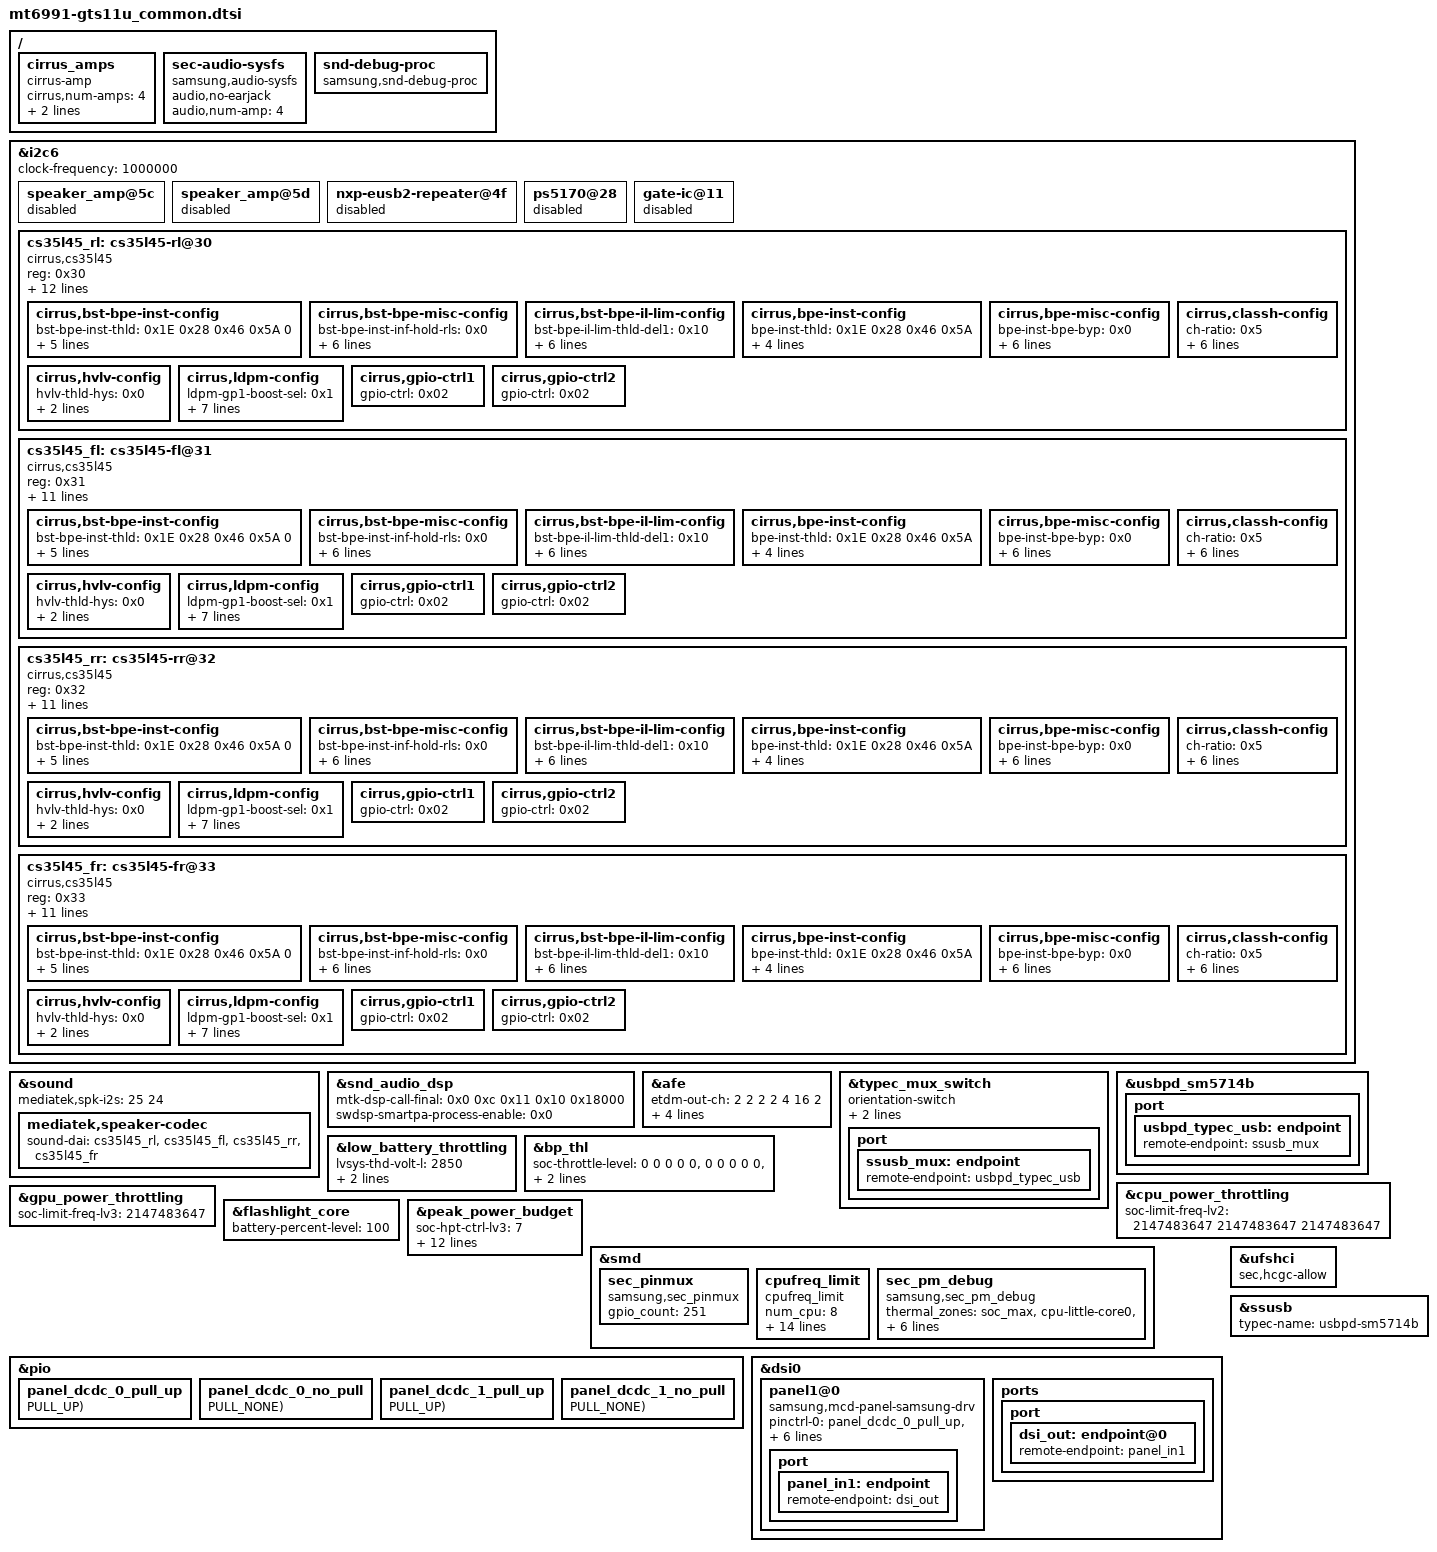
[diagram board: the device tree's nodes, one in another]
/* Generated by Samsung for MTK vendor board
 * If these files should be changed, then please make a sync with MTK
*/

/* Add Samsung configuration over here */

/ {
	fragment@model {
		target-path = "/";
		__overlay__ {
			cirrus_amps {
				compatible = "cirrus-amp";
				cirrus,num-amps = <4>;
				/* i2c addr 0x30, 0x31, 0x32, 0x33 */
				cirrus,amps = <&cs35l45_rl &cs35l45_fl &cs35l45_rr &cs35l45_fr>;
			};

			sec-audio-sysfs {
				compatible = "samsung,audio-sysfs";
				status = "okay";
				audio,no-earjack;
				audio,num-amp = <4>;
			};

			snd-debug-proc {
				compatible = "samsung,snd-debug-proc";
				status = "okay";
			};

		}; /* end of __overlay__ */
	}; /* end of fragment */
}; /* end of root */

&i2c6 {
	speaker_amp@5c {
		status = "disabled";
	};

	speaker_amp@5d {
		status = "disabled";
	};

	nxp-eusb2-repeater@4f {
		status = "disabled";
	};

	ps5170@28 {
		status = "disabled";
	};

	gate-ic@11 {
		status = "disabled";
	};
};

&i2c6 {
	clock-frequency = <1000000>;

	cs35l45_rl: cs35l45-rl@30 {
		compatible = "cirrus,cs35l45";
		#sound-dai-cells = <0>;
		reg = <0x30>;
		status = "okay";
		interrupt-parent = <&pio>;
		interrupts = <5 8>;
		reset-gpios = <&pio 91 0>;
		sound-name-prefix = "RL"; /* RearLeft */
		cirrus,mfd-suffix = "";
		cirrus,bd-suffix = "_2";
		cirrus,use-tdm-slots;
		cirrus,asp-sdout-hiz-ctrl = <0x3>;

		cirrus,ngate-ch1-hold = <0x2>;
		cirrus,ngate-ch1-thr = <0x6>;
		cirrus,ngate-ch2-hold = <0x2>;
		cirrus,ngate-ch2-thr = <0x6>;

		cirrus,bst-bpe-inst-config {
			bst-bpe-inst-thld = <0x1E 0x28 0x46 0x5A 0>;
			bst-bpe-inst-ilim = <0 0x04 0x0C 0x14 0x3C>;
			bst-bpe-inst-ss-ilim = <0 0x00 0x04 0x08 0x1C>;
			bst-bpe-inst-atk-rate = <0 0x3 0x6 0x6 0>;
			bst-bpe-inst-hold-time = <0x2 0x2 0x2 0x2 0>;
			bst-bpe-inst-rls-rate = <0x06 0x06 0x06 0x06 0>;
		};

		cirrus,bst-bpe-misc-config {
			bst-bpe-inst-inf-hold-rls = <0x0>;
			bst-bpe-il-lim-mode = <0x0>;
			bst-bpe-out-opmode-sel = <0x0>;
			bst-bpe-inst-l3-byp = <0x1>;
			bst-bpe-inst-l2-byp = <0x1>;
			bst-bpe-inst-l1-byp = <0x0>;
			bst-bpe-filt-sel = <0x0>;
		};

		cirrus,bst-bpe-il-lim-config {
			bst-bpe-il-lim-thld-del1 = <0x10>;
			bst-bpe-il-lim-thld-del2 = <0x00>;
			bst-bpe-il-lim1-thld = <0x2c>;
			bst-bpe-il-lim-thld-hyst = <0x00>;
			bst-bpe-il-lim-dly-hyst = <0x00>;
			bst-bpe-il-lim2-dly = <0x04>;
			bst-bpe-il-lim1-dly = <0x04>;
		};

		cirrus,bpe-inst-config {
			bpe-inst-thld = <0x1E 0x28 0x46 0x5A>;
			bpe-inst-attn = <0x0A 0x06 0x0C 0x06>;
			bpe-inst-atk-rate = <0x00 0x01 0x06 0x06>;
			bpe-inst-hold-time = <0x02 0x02 0x02 0x02>;
			bpe-inst-rls-rate = <0x0A 0x08 0x05 0x05>;
		};

		cirrus,bpe-misc-config {
			bpe-inst-bpe-byp = <0x0>;
			bpe-inst-inf-hold-rls = <0x0>;
			bpe-inst-l3-byp = <0x1>;
			bpe-inst-l2-byp = <0x1>;
			bpe-inst-l1-byp = <0x0>;
			bpe-mode-sel = <0x0>;
			bpe-filt-sel = <0x0>;
		};

		cirrus,classh-config {
			ch-ratio = <0x5>;
			ch-rel-rate = <0x4>;
			ch-ovb-thld1 = <0x82>;
			ch-ovb-thlddelta = <0x28>;
			ch-vdd-bst-max = <0xFA>;
			ch-ovb-ratio = <0x01>;
			ch-thld1-offset = <0x02d>;
		};

		cirrus,hvlv-config {
			hvlv-thld-hys = <0x0>;
			hvlv-thld = <0x8>;
			hvlv-dly = <0x1>;
		};

		cirrus,ldpm-config {
			ldpm-gp1-boost-sel = <0x1>;
			ldpm-gp1-amp-sel = <0x1>;
			ldpm-gp1-delay = <0x6>;
			ldpm-gp1-pcm-thld = <0x6>;
			ldpm-gp2-imon-sel = <0x1>;
			ldpm-gp2-vmon-sel = <0x1>;
			ldpm-gp2-delay = <0x6>;
			ldpm-gp2-pcm-thld = <0x6>;
		};

		cirrus,gpio-ctrl1 {
			gpio-ctrl = <0x02>;
		};
		cirrus,gpio-ctrl2 {
			gpio-ctrl = <0x02>;
		};
	};

	cs35l45_fl: cs35l45-fl@31 {
		compatible = "cirrus,cs35l45";
		#sound-dai-cells = <0>;
		reg = <0x31>;
		status = "okay";
		interrupt-parent = <&pio>;
		interrupts = <5 8>;
		/* reset-gpios = <&pio 91 0>; */
		sound-name-prefix = "FL"; /* FrontLeft */
		cirrus,mfd-suffix = "_b";
		cirrus,bd-suffix = "_0";
		cirrus,use-tdm-slots;
		cirrus,asp-sdout-hiz-ctrl = <0x3>;

		cirrus,ngate-ch1-hold = <0x2>;
		cirrus,ngate-ch1-thr = <0x6>;
		cirrus,ngate-ch2-hold = <0x2>;
		cirrus,ngate-ch2-thr = <0x6>;

		cirrus,bst-bpe-inst-config {
			bst-bpe-inst-thld = <0x1E 0x28 0x46 0x5A 0>;
			bst-bpe-inst-ilim = <0 0x04 0x0C 0x14 0x3C>;
			bst-bpe-inst-ss-ilim = <0 0x00 0x04 0x08 0x1C>;
			bst-bpe-inst-atk-rate = <0 0x3 0x6 0x6 0>;
			bst-bpe-inst-hold-time = <0x2 0x2 0x2 0x2 0>;
			bst-bpe-inst-rls-rate = <0x06 0x06 0x06 0x06 0>;
		};

		cirrus,bst-bpe-misc-config {
			bst-bpe-inst-inf-hold-rls = <0x0>;
			bst-bpe-il-lim-mode = <0x0>;
			bst-bpe-out-opmode-sel = <0x0>;
			bst-bpe-inst-l3-byp = <0x1>;
			bst-bpe-inst-l2-byp = <0x1>;
			bst-bpe-inst-l1-byp = <0x0>;
			bst-bpe-filt-sel = <0x0>;
		};

		cirrus,bst-bpe-il-lim-config {
			bst-bpe-il-lim-thld-del1 = <0x10>;
			bst-bpe-il-lim-thld-del2 = <0x00>;
			bst-bpe-il-lim1-thld = <0x2c>;
			bst-bpe-il-lim-thld-hyst = <0x00>;
			bst-bpe-il-lim-dly-hyst = <0x00>;
			bst-bpe-il-lim2-dly = <0x04>;
			bst-bpe-il-lim1-dly = <0x04>;
		};

		cirrus,bpe-inst-config {
			bpe-inst-thld = <0x1E 0x28 0x46 0x5A>;
			bpe-inst-attn = <0x0A 0x06 0x0C 0x06>;
			bpe-inst-atk-rate = <0x00 0x01 0x06 0x06>;
			bpe-inst-hold-time = <0x02 0x02 0x02 0x02>;
			bpe-inst-rls-rate = <0x0A 0x08 0x05 0x05>;
		};

		cirrus,bpe-misc-config {
			bpe-inst-bpe-byp = <0x0>;
			bpe-inst-inf-hold-rls = <0x0>;
			bpe-inst-l3-byp = <0x1>;
			bpe-inst-l2-byp = <0x1>;
			bpe-inst-l1-byp = <0x0>;
			bpe-mode-sel = <0x0>;
			bpe-filt-sel = <0x0>;
		};

		cirrus,classh-config {
			ch-ratio = <0x5>;
			ch-rel-rate = <0x4>;
			ch-ovb-thld1 = <0x82>;
			ch-ovb-thlddelta = <0x28>;
			ch-vdd-bst-max = <0xFA>;
			ch-ovb-ratio = <0x01>;
			ch-thld1-offset = <0x02d>;
		};

		cirrus,hvlv-config {
			hvlv-thld-hys = <0x0>;
			hvlv-thld = <0x8>;
			hvlv-dly = <0x1>;
		};

		cirrus,ldpm-config {
			ldpm-gp1-boost-sel = <0x1>;
			ldpm-gp1-amp-sel = <0x1>;
			ldpm-gp1-delay = <0x6>;
			ldpm-gp1-pcm-thld = <0x6>;
			ldpm-gp2-imon-sel = <0x1>;
			ldpm-gp2-vmon-sel = <0x1>;
			ldpm-gp2-delay = <0x6>;
			ldpm-gp2-pcm-thld = <0x6>;
		};

		cirrus,gpio-ctrl1 {
			gpio-ctrl = <0x02>;
		};
		cirrus,gpio-ctrl2 {
			gpio-ctrl = <0x02>;
		};
	};

	cs35l45_rr: cs35l45-rr@32 {
		compatible = "cirrus,cs35l45";
		#sound-dai-cells = <0>;
		reg = <0x32>;
		status = "okay";
		interrupt-parent = <&pio>;
		interrupts = <5 8>;
		/* reset-gpios = <&pio 91 0>; */
		sound-name-prefix = "RR"; /* RearRight */
		cirrus,mfd-suffix = "_r";
		cirrus,bd-suffix = "_3";
		cirrus,use-tdm-slots;
		cirrus,asp-sdout-hiz-ctrl = <0x3>;

		cirrus,ngate-ch1-hold = <0x2>;
		cirrus,ngate-ch1-thr = <0x6>;
		cirrus,ngate-ch2-hold = <0x2>;
		cirrus,ngate-ch2-thr = <0x6>;

		cirrus,bst-bpe-inst-config {
			bst-bpe-inst-thld = <0x1E 0x28 0x46 0x5A 0>;
			bst-bpe-inst-ilim = <0 0x04 0x0C 0x14 0x3C>;
			bst-bpe-inst-ss-ilim = <0 0x00 0x04 0x08 0x1C>;
			bst-bpe-inst-atk-rate = <0 0x3 0x6 0x6 0>;
			bst-bpe-inst-hold-time = <0x2 0x2 0x2 0x2 0>;
			bst-bpe-inst-rls-rate = <0x06 0x06 0x06 0x06 0>;
		};

		cirrus,bst-bpe-misc-config {
			bst-bpe-inst-inf-hold-rls = <0x0>;
			bst-bpe-il-lim-mode = <0x0>;
			bst-bpe-out-opmode-sel = <0x0>;
			bst-bpe-inst-l3-byp = <0x1>;
			bst-bpe-inst-l2-byp = <0x1>;
			bst-bpe-inst-l1-byp = <0x0>;
			bst-bpe-filt-sel = <0x0>;
		};

		cirrus,bst-bpe-il-lim-config {
			bst-bpe-il-lim-thld-del1 = <0x10>;
			bst-bpe-il-lim-thld-del2 = <0x00>;
			bst-bpe-il-lim1-thld = <0x2c>;
			bst-bpe-il-lim-thld-hyst = <0x00>;
			bst-bpe-il-lim-dly-hyst = <0x00>;
			bst-bpe-il-lim2-dly = <0x04>;
			bst-bpe-il-lim1-dly = <0x04>;
		};

		cirrus,bpe-inst-config {
			bpe-inst-thld = <0x1E 0x28 0x46 0x5A>;
			bpe-inst-attn = <0x0A 0x06 0x0C 0x06>;
			bpe-inst-atk-rate = <0x00 0x01 0x06 0x06>;
			bpe-inst-hold-time = <0x02 0x02 0x02 0x02>;
			bpe-inst-rls-rate = <0x0A 0x08 0x05 0x05>;
		};

		cirrus,bpe-misc-config {
			bpe-inst-bpe-byp = <0x0>;
			bpe-inst-inf-hold-rls = <0x0>;
			bpe-inst-l3-byp = <0x1>;
			bpe-inst-l2-byp = <0x1>;
			bpe-inst-l1-byp = <0x0>;
			bpe-mode-sel = <0x0>;
			bpe-filt-sel = <0x0>;
		};

		cirrus,classh-config {
			ch-ratio = <0x5>;
			ch-rel-rate = <0x4>;
			ch-ovb-thld1 = <0x82>;
			ch-ovb-thlddelta = <0x28>;
			ch-vdd-bst-max = <0xFA>;
			ch-ovb-ratio = <0x01>;
			ch-thld1-offset = <0x02d>;
		};

		cirrus,hvlv-config {
			hvlv-thld-hys = <0x0>;
			hvlv-thld = <0x8>;
			hvlv-dly = <0x1>;
		};

		cirrus,ldpm-config {
			ldpm-gp1-boost-sel = <0x1>;
			ldpm-gp1-amp-sel = <0x1>;
			ldpm-gp1-delay = <0x6>;
			ldpm-gp1-pcm-thld = <0x6>;
			ldpm-gp2-imon-sel = <0x1>;
			ldpm-gp2-vmon-sel = <0x1>;
			ldpm-gp2-delay = <0x6>;
			ldpm-gp2-pcm-thld = <0x6>;
		};

		cirrus,gpio-ctrl1 {
			gpio-ctrl = <0x02>;
		};
		cirrus,gpio-ctrl2 {
			gpio-ctrl = <0x02>;
		};
	};

	cs35l45_fr: cs35l45-fr@33 {
		compatible = "cirrus,cs35l45";
		#sound-dai-cells = <0>;
		reg = <0x33>;
		status = "okay";
		interrupt-parent = <&pio>;
		interrupts = <5 8>;
		/* reset-gpios = <&pio 91 0>; */
		sound-name-prefix = "FR"; /* FrontRight */
		cirrus,mfd-suffix = "_br";
		cirrus,bd-suffix = "_1";
		cirrus,use-tdm-slots;
		cirrus,asp-sdout-hiz-ctrl = <0x3>;

		cirrus,ngate-ch1-hold = <0x2>;
		cirrus,ngate-ch1-thr = <0x6>;
		cirrus,ngate-ch2-hold = <0x2>;
		cirrus,ngate-ch2-thr = <0x6>;

		cirrus,bst-bpe-inst-config {
			bst-bpe-inst-thld = <0x1E 0x28 0x46 0x5A 0>;
			bst-bpe-inst-ilim = <0 0x04 0x0C 0x14 0x3C>;
			bst-bpe-inst-ss-ilim = <0 0x00 0x04 0x08 0x1C>;
			bst-bpe-inst-atk-rate = <0 0x3 0x6 0x6 0>;
			bst-bpe-inst-hold-time = <0x2 0x2 0x2 0x2 0>;
			bst-bpe-inst-rls-rate = <0x06 0x06 0x06 0x06 0>;
		};

		cirrus,bst-bpe-misc-config {
			bst-bpe-inst-inf-hold-rls = <0x0>;
			bst-bpe-il-lim-mode = <0x0>;
			bst-bpe-out-opmode-sel = <0x0>;
			bst-bpe-inst-l3-byp = <0x1>;
			bst-bpe-inst-l2-byp = <0x1>;
			bst-bpe-inst-l1-byp = <0x0>;
			bst-bpe-filt-sel = <0x0>;
		};

		cirrus,bst-bpe-il-lim-config {
			bst-bpe-il-lim-thld-del1 = <0x10>;
			bst-bpe-il-lim-thld-del2 = <0x00>;
			bst-bpe-il-lim1-thld = <0x2c>;
			bst-bpe-il-lim-thld-hyst = <0x00>;
			bst-bpe-il-lim-dly-hyst = <0x00>;
			bst-bpe-il-lim2-dly = <0x04>;
			bst-bpe-il-lim1-dly = <0x04>;
		};

		cirrus,bpe-inst-config {
			bpe-inst-thld = <0x1E 0x28 0x46 0x5A>;
			bpe-inst-attn = <0x0A 0x06 0x0C 0x06>;
			bpe-inst-atk-rate = <0x00 0x01 0x06 0x06>;
			bpe-inst-hold-time = <0x02 0x02 0x02 0x02>;
			bpe-inst-rls-rate = <0x0A 0x08 0x05 0x05>;
		};

		cirrus,bpe-misc-config {
			bpe-inst-bpe-byp = <0x0>;
			bpe-inst-inf-hold-rls = <0x0>;
			bpe-inst-l3-byp = <0x1>;
			bpe-inst-l2-byp = <0x1>;
			bpe-inst-l1-byp = <0x0>;
			bpe-mode-sel = <0x0>;
			bpe-filt-sel = <0x0>;
		};

		cirrus,classh-config {
			ch-ratio = <0x5>;
			ch-rel-rate = <0x4>;
			ch-ovb-thld1 = <0x82>;
			ch-ovb-thlddelta = <0x28>;
			ch-vdd-bst-max = <0xFA>;
			ch-ovb-ratio = <0x01>;
			ch-thld1-offset = <0x02d>;
		};

		cirrus,hvlv-config {
			hvlv-thld-hys = <0x0>;
			hvlv-thld = <0x8>;
			hvlv-dly = <0x1>;
		};

		cirrus,ldpm-config {
			ldpm-gp1-boost-sel = <0x1>;
			ldpm-gp1-amp-sel = <0x1>;
			ldpm-gp1-delay = <0x6>;
			ldpm-gp1-pcm-thld = <0x6>;
			ldpm-gp2-imon-sel = <0x1>;
			ldpm-gp2-vmon-sel = <0x1>;
			ldpm-gp2-delay = <0x6>;
			ldpm-gp2-pcm-thld = <0x6>;
		};

		cirrus,gpio-ctrl1 {
			gpio-ctrl = <0x02>;
		};
		cirrus,gpio-ctrl2 {
			gpio-ctrl = <0x02>;
		};
	};
};

&sound {
	mediatek,spk-i2s = <25 24>;
	mediatek,speaker-codec {
		/* i2c addr 0x30, 0x31, 0x32, 0x33 */
		sound-dai = <&cs35l45_rl>, <&cs35l45_fl>, <&cs35l45_rr>, <&cs35l45_fr>;
	};
};

/* feature : $enable $dl_mem $ul_mem $ref_mem $size */
&snd_audio_dsp {
	mtk-dsp-call-final = <0x0 0xc 0x11 0x10 0x18000>;
	swdsp-smartpa-process-enable = <0x0>;
};

&afe {
	etdm-out-ch = <2 2 2 2 4 16 2>;
	etdm-in-ch = <2 2 2 2 4 16 16>;
	etdm-out-format = <0 0 0 0 4 4 4>;
	etdm-in-format = <0 0 0 0 4 4 4>;
	mediatek,ap-dmic = <1>;
};

&typec_mux_switch {
	orientation-switch;
	mode-switch;
	accessory;
	port {
		ssusb_mux: endpoint {
			remote-endpoint = <&usbpd_typec_usb>;
		};
	};
};

&usbpd_sm5714b {
	port {
		usbpd_typec_usb: endpoint {
			remote-endpoint = <&ssusb_mux>;
		};
	};
};

&low_battery_throttling {
	lvsys-thd-volt-l = <2850>;
	lvsys-thd-volt-h = <3100>;
	lvsys-cust-thl-lv = <1>;
};

&bp_thl {
	soc-throttle-level = <0 0 0 0 0>, //temperature stage 0
		<0 0 0 0 0>, //temperature stage 1
		<0 0 0 0 0>, //temperature stage 2
		<0 0 0 0 0>; //temperature stage 3
	soc-limit-threshold = <80 60 30 5>;
};

&cpu_power_throttling {
	soc-limit-freq-lv2 = < 2147483647  2147483647 2147483647 >;
};

&gpu_power_throttling {
	soc-limit-freq-lv3 = <2147483647>;
};

&flashlight_core {
	battery-percent-level = <100>;
};

&peak_power_budget {
	soc-hpt-ctrl-lv3 = <7>;

	/* The HW PT at each battery throttle level. */
	cpub-sf-default = <3>;
	cpum-sf-default = <4>;
	gpu-sf-default = <7>;

	soc-sf-cpub-lv1 = <3>;
	soc-sf-cpum-lv1 = <4>;
	soc-sf-gpu-lv1 = <7>;

	soc-sf-cpub-lv2 = <3>;
	soc-sf-cpum-lv2 = <4>;
	soc-sf-gpu-lv2 = <7>;

	soc-sf-cpub-lv3 = <3>;
	soc-sf-cpum-lv3 = <4>;
	soc-sf-gpu-lv3 = <7>;
};

&smd {

	sec_pinmux {
		status = "okay";
		compatible = "samsung,sec_pinmux";

		gpio_count = <251>;
	};

	cpufreq_limit {
		status = "okay";
		compatible = "cpufreq_limit";

		num_cpu = <8>;
		ltl_cpu_start = <0>;
		mid_cpu_start = <4>;
		big_cpu_start = <7>;
		ltl_min_lock_freq = <1200000>;
		big_max_lock_freq = <800000>;
		ltl_divider = <4>;

		ltl_boost_table = <
			3730000 2400000
			3600000 2300000
			3500000 2200000
			3400000 2100000
			2600000 1800000
			2200000 1500000
			1800000 1300000
			600000 1100000
		>;

		ltl_limit_table = <
			3730000	4294967295	/* 3730000 ~ : max freq */
			3600000 2300000
			3500000 2200000
			3400000 2100000
			2600000 1800000
			2200000 1500000
			1800000 1300000
			600000 1100000
		>;

		mid_boost_table = <
			3730000 3300000
			3600000 3200000
			3500000 3100000
			3300000 3000000
			3200000 2900000
			3100000 2800000
			3000000 2700000
			2900000 2600000
			2800000 2500000
			2700000 2400000
			2600000 2300000
			2500000 2200000
			2400000 2100000
			2300000 2000000
			2200000 1900000
			2100000 1800000
			2000000 1700000
			1900000 1600000
			1800000 1500000
			1700000 1400000
			1600000 1300000
			1500000 1200000
			1400000 1100000
			1300000 1000000
			1200000 900000
			600000 800000
		>;

		mid_limit_table = <
			3730000	4294967295	/* 3730000 ~ : max freq */
			3600000 3200000
			3500000 3100000
			3300000 3000000
			3200000 2900000
			3100000 2800000
			3000000 2700000
			2900000 2600000
			2800000 2500000
			2700000 2400000
			2600000 2300000
			2500000 2200000
			2400000 2100000
			2300000 2000000
			2200000 1900000
			2100000 1800000
			2000000 1700000
			1900000 1600000
			1800000 1500000
			1700000 1400000
			1600000 1300000
			1500000 1200000
			1400000 1100000
			1300000 1000000
			1200000 900000
			600000 800000
		>;

	};

	sec_pm_debug {
	status = "okay";
	compatible = "samsung,sec_pm_debug";

	thermal_zones = "soc_max",
		"cpu-little-core0", "cpu-little-core1", "cpu-little-core2", "cpu-little-core3",
		"cpu-medium-core4-0", "cpu-medium-core4-1", "cpu-medium-core5-0", "cpu-medium-core5-1",
		"cpu-medium-core6-0", "cpu-medium-core6-1", "cpu-big-core7-0", "cpu-big-core7-1",
		"gpu0", "gpu1", "gpu2";
	};
};

&pio {
	panel_dcdc_0_pull_up: panel_dcdc_0_pull_up {
		GPIO_CONFIG_PUD(AP,pio,18, FUNC_INPUT, PULL_UP);
	};

	panel_dcdc_0_no_pull: panel_dcdc_0_no_pull {
		GPIO_CONFIG_PUD(AP,pio,18, FUNC_INPUT, PULL_NONE);
	};

	panel_dcdc_1_pull_up: panel_dcdc_1_pull_up {
		GPIO_CONFIG_PUD(AP,pio,22, FUNC_INPUT, PULL_UP);
	};

	panel_dcdc_1_no_pull: panel_dcdc_1_no_pull {
		GPIO_CONFIG_PUD(AP,pio,22, FUNC_INPUT, PULL_NONE);
	};
};

&dsi0 {
	status = "okay";
	#address-cells = <1>;
	#size-cells = <0>;

	panel1@0 {
		compatible =  "samsung,mcd-panel-samsung-drv";
		pinctrl-names =
			"default",
			"panel_pinctrl_power_before_on",
			"panel_pinctrl_power_after_off";

		pinctrl-0 = <&panel_dcdc_0_pull_up>, <&panel_dcdc_1_pull_up>;
		pinctrl-1 = <&panel_dcdc_0_pull_up>, <&panel_dcdc_1_pull_up>;
		pinctrl-2 = <&panel_dcdc_0_no_pull>, <&panel_dcdc_1_no_pull>;

		reg = <0>;
		port {
			panel_in1: endpoint {
				remote-endpoint = <&dsi_out>;
			};
		};
	};

	ports {
		port {
			dsi_out: endpoint@0 {
				remote-endpoint = <&panel_in1>;
			};
		};
	};
};

&ufshci {
	sec,hcgc-allow;
};

&ssusb {
	typec-name = "usbpd-sm5714b";
};
